# LPC122x register map
File version: 2
Registers are 32-bit, read-write, reset 0x0 unless marked. A register's access mark holds for its fields unless they carry their own. Offsets are from the block's base; [hi:lo] are bit positions; {n}, {i} and the like mark numbered series; 'fields as' and 'values as' point back to an identical list.

## SYSCON — Product name title=UM10441 Chapter title=LPC122x System control (SYSCON) Modification date=8/18/2011 Major revision=2 Minor revision=0
Base 0x40048000
0x00 SYSMEMREMAP — System memory remap
  [1:0] MAP — System memory remap. Value 0x3 is reserved.
    0=BOOT_LOADER_MODE_IN (Boot Loader Mode. Interrupt vectors are re-mapped to Boot ROM.); 1=USER_RAM_MODE_INTER (User RAM Mode. Interrupt vectors are re-mapped to Static RAM.); 2=USER_FLASH_MODE_INT (User Flash Mode. Interrupt vectors are not re-mapped and reside in Flash.)
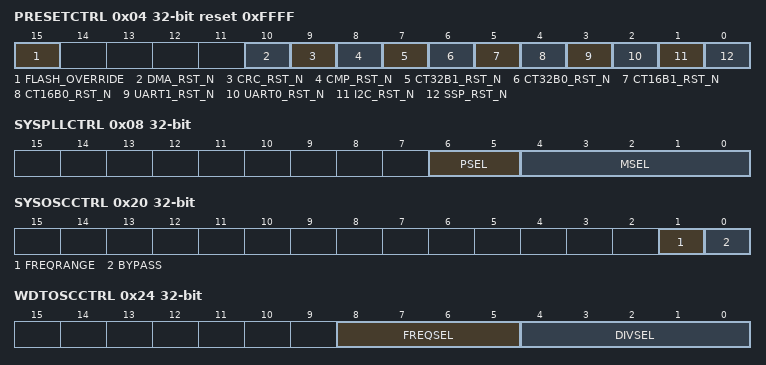
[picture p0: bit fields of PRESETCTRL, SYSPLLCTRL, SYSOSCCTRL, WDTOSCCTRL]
0x04 PRESETCTRL reset 0xFFFF — Peripheral reset control and flash timing overwrite
  [15] FLASH_OVERRIDE — Flash read mode. The default is 1-cycle flash read access. At higher operating frequencies the multi-cycle read mode must be used to allow 2, 3, 4, or 5-cycle read configuration. If multi-cycle read mode is selected, the number of cycles can be configured in the FLASHCFG register (see Table 52).
    0=FLASH_MULTI_CYCLE_RE (Flash multi-cycle read mode.); 1=FLASH_1_CYCLE_READ_M (Flash 1-cycle read mode.)
  [10] DMA_RST_N — Micro DMA reset control
    0=DMA_RESET_ENABLED; 1=DMA_RESET_DE_ASSERTE (DMA reset de-asserted)
  [9] CRC_RST_N — CRC reset control
    0=CRC_RESET_ENABLED; 1=CRC_RESET_DE_ASSERTE (CRC reset de-asserted)
  [8] CMP_RST_N — Comparator reset control
    0=COMPARATOR_RESET_ENA (Comparator reset enabled); 1=COMPARATOR_RESET_DE_ (Comparator reset de-asserted)
  [7] CT32B1_RST_N — 32-bit counter/timer 1 (CT32B1) reset control
    0=CT32B1_RESET_ENABLED; 1=CT32B1_RESET_DE_ASSE (CT32B1 reset de-asserted)
  [6] CT32B0_RST_N — 32-bit counter/timer 0 (CT32B0) reset control
    0=CT32B0_RESET_ENABLED; 1=CT32B0_RESET_DE_ASSE (CT32B0 reset de-asserted)
  [5] CT16B1_RST_N — 16-bit counter/timer 1 (CT16B1) reset control
    0=CT16B1_RESET_ENABLED; 1=CT16B1_RESET_DE_ASSE (CT16B1 reset de-asserted)
  [4] CT16B0_RST_N — 16-bit counter/timer 0 (CT16B0) reset control
    0=CT16B0_RESET_ENABLED; 1=CT16B0_RESET_DE_ASSE (CT16B0 reset de-asserted)
  [3] UART1_RST_N — UART1 reset control
    0=UART1_RESET_ENABLED; 1=UART1_RESET_DE_ASSER (UART1 reset de-asserted)
  [2] UART0_RST_N — UART0 reset control
    0=UART0_RESET_ENABLED; 1=UART0_RESET_DE_ASSER (UART0 reset de-asserted)
  [1] I2C_RST_N — I2C reset control
    0=I2C_RESET_ENABLED; 1=I2C_RESET_DE_ASSERTE (I2C reset de-asserted)
  [0] SSP_RST_N — SSP reset control
    0=SSP_RESET_ENABLED; 1=SSP_RESET_DE_ASSERTE (SSP reset de-asserted)
0x08 SYSPLLCTRL — System PLL control
  [6:5] PSEL — Post divider ratio P. The division ratio is 2xP.
    0=P_EQ_1 (P = 1); 1=P_EQ_2 (P = 2); 2=P_EQ_4 (P = 4); 3=P_EQ_8 (P = 8)
  [4:0] MSEL — Feedback divider value. The division value M is the programmed MSEL value + 1. 00000: Division ratio M = 1 to 11111: Division ratio M = 32
0x0C SYSPLLSTAT ro — System PLL status
  [0] LOCK — PLL lock status
    0=PLL_NOT_LOCKED; 1=PLL_LOCKED
0x20 SYSOSCCTRL — System oscillator control
  [1] FREQRANGE — Determines frequency range for Low-power oscillator.
    0=1__20_MHZ_FREQUENCY (1 - 20 MHz frequency range.); 1=15__25_MHZ_FREQUENC (15 - 25 MHz frequency range)
  [0] BYPASS — Bypass system oscillator
    0=OSCILLATOR_IS_NOT_BY (Oscillator is not bypassed.); 1=BYPASS_ENABLED_PLL_ (Bypass enabled. PLL input (sys_osc_clk) is fed directly from the XTALIN and XTALOUT pins.)
0x24 WDTOSCCTRL — Watchdog oscillator control
  [8:5] FREQSEL — Select watchdog oscillator analog output frequency (Fclkana).
    1=0_5_MHZ; 2=0_8_MHZ; 3=1_1_MHZ; 4=1_4_MHZ; 5=1_6_MHZ; 6=1_8_MHZ; 7=2_0_MHZ; 8=2_2_MHZ; 9=2_4_MHZ; 10=2_6_MHZ; 11=2_7_MHZ; 12=2_9_MHZ; 13=3_1_MHZ; 14=3_2_MHZ; 15=3_4_MHZ
  [4:0] DIVSEL — Select divider for Fclkana. wdt_osc_clk = Fclkana/ (2 x (1 + DIVSEL)) 00000: 2 x (1 + DIVSEL) = 2 00001: 2 x (1 + DIVSEL) = 4 to 11111: 2 x (1 + DIVSEL) = 64
0x28 IRCCTRL reset 0x80 — IRC control
  [7:0] TRIM — Trim value
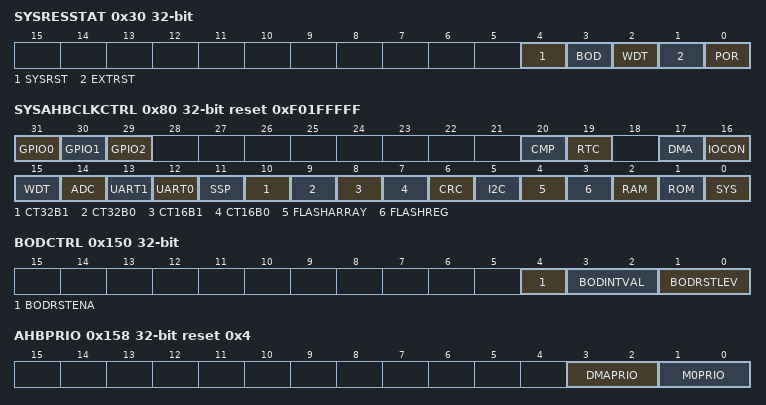
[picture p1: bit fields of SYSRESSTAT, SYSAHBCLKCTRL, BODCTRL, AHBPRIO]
0x30 SYSRESSTAT — System reset status register
  [4] SYSRST — Status of the software system reset.The ARM software reset has the same effect as the hardware reset using the RESET pin.
    0=NO_SYSTEM_RESET_DETE (no System reset detected); 1=SYSTEM_RESET_DETECTE (System reset detected)
  [3] BOD — Status of the Brown-out detect reset
    0=NO_BOD_RESET_DETECTE (no BOD reset detected); 1=BOD_RESET_DETECTED
  [2] WDT — Status of the Watchdog reset
    0=NO_WDT_RESET_DETECTE (no WDT reset detected); 1=WDT_RESET_DETECTED
  [1] EXTRST — reset status
    0=NO_RESET_EVENT_DETEC (no RESET event detected); 1=RESET_DETECTED
  [0] POR — POR reset status
    0=NO_POR_DETECTED; 1=POR_DETECTED
0x40 SYSPLLCLKSEL — System PLL clock source select
  [1:0] SEL — System PLL clock source
    0=IRC_OSCILLATOR; 1=SYSTEM_OSCILLATOR
0x44 SYSPLLCLKUEN — System PLL clock source update enable
  [0] ENA — Enable system PLL clock source update
    0=NO_CHANGE; 1=UPDATE_CLOCK_SOURCE
0x70 MAINCLKSEL — Main clock source select
  [1:0] SEL — Clock source for main clock
    0=IRC_OSCILLATOR; 1=INPUT_CLOCK_TO_SYSTE (Input clock to system PLL); 2=WDT_OSCILLATOR; 3=SYSTEM_PLL_CLOCK_OUT
0x74 MAINCLKUEN — Main clock source update enable
  [0] ENA — Enable main clock source update
    0=NO_CHANGE; 1=UPDATE_CLOCK_SOURCE
0x78 SYSAHBCLKDIV reset 0x1 — System AHB clock divider
  [7:0] DIV — System AHB clock divider values 0: System clock disabled. 1: Divide by 1. to 255: Divide by 255.
0x80 SYSAHBCLKCTRL reset 0xF01FFFFF — System AHB clock control
  [31] GPIO0 — Enables clock for GPIO port 0.
    0=DISABLE; 1=ENABLE
  [30] GPIO1 — Enables clock for GPIO port 1.
    0=DISABLE; 1=ENABLE
  [29] GPIO2 — Enables clock for GPIO port 2.
    0=DISABLE; 1=ENABLE
  [20] CMP — Enables clock for comparator.
    0=DISABLE; 1=ENABLE
  [19] RTC — Enables clock for RTC. If the RTC clock source is disabled, select the RTC clock source first, before re-enabling the RTC through this bit (see Table 58).
    0=DISABLE; 1=ENABLE
  [17] DMA — Enables clock for micro DMA.
    0=DISABLE; 1=ENABLE
  [16] IOCON — Enables clock for IO configuration block.
    0=DISABLE; 1=ENABLE
  [15] WDT — Enables clock for WDT.
    0=DISABLE; 1=ENABLE
  [14] ADC — Enables clock for ADC.
    0=DISABLE; 1=ENABLE
  [13] UART1 — Enables clock for UART1. Note that the UART1 pins must be configured in the IOCON block before the UART1 clock can be enabled.
    0=DISABLE; 1=ENABLE
  [12] UART0 — Enables clock for UART0. Note that the UART0 pins must be configured in the IOCON block before the UART0 clock can be enabled.
    0=DISABLE; 1=ENABLE
  [11] SSP — Enables clock for SSP.
    0=DISABLE; 1=ENABLE
  [10] CT32B1 — Enables clock for 32-bit counter/timer 1.
    0=DISABLE; 1=ENABLE
  [9] CT32B0 — Enables clock for 32-bit counter/timer 0.
    0=DISABLE; 1=ENABLE
  [8] CT16B1 — Enables clock for 16-bit counter/timer 1.
    0=DISABLE; 1=ENABLE
  [7] CT16B0 — Enables clock for 16-bit counter/timer 0.
    0=DISABLE; 1=ENABLE
  [6] CRC — Enables clock for CRC.
    0=DISABLE; 1=ENABLE
  [5] I2C — Enables clock for I2C.
    0=DISABLE; 1=ENABLE
  [4] FLASHARRAY — Enables clock for flash array.
    0=DISABLE; 1=ENABLE
  [3] FLASHREG — Enables clock for flash controller registers.
    0=DISABLE; 1=ENABLE
  [2] RAM — Enables clock for RAM.
    0=DISABLE; 1=ENABLE
  [1] ROM — Enables clock for ROM.
    0=DISABLE; 1=ENABLE
  [0] SYS — Enables clock for AHB to APB bridge, to the AHB matrix, to the Cortex-M0 FCLK and HCLK, to the SysCon, and to the PMU. This bit is read only.
    1=ENABLE
0x94 SSPCLKDIV — SSP clock divder
  [7:0] DIV — SSP0_PCLK clock divider values 0: Disable SSP0_PCLK. 1: Divide by 1. to 255: Divide by 255.
0x98 UART0CLKDIV — UART0 clock divider
  [7:0] DIV — UART0_PCLK clock divider values 0: Disable UART0_PCLK. 1: Divide by 1. to 255: Divide by 255.
0x9C UART1CLKDIV — UART1 clock divider
  [7:0] DIV — UART1_PCLK clock divider values 0: Disable UART1_PCLK. 1: Divide by 1. to 255: Divide by 255.
0xA0 RTCCLKDIV — RTC clock divider
  [7:0] DIV — RTC_PCLK clock divider values 0: Disable RTC_PCLK. 1: Divide by 1. to 255: Divide by 255.
0xE0 CLKOUTCLKSEL — CLKOUT clock source select
  [1:0] SEL — CLKOUT clock source
    0=IRC_OSCILLATOR; 1=SYSTEM_OSCILLATOR; 2=WATCHDOG_OSCILLATOR; 3=MAIN_CLOCK
0xE4 CLKOUTUEN — CLKOUT clock source update enable
  [0] ENA — Enable CLKOUT clock source update
    0=NO_CHANGE; 1=UPDATE_CLOCK_SOURCE
0xE8 CLKOUTDIV — CLKOUT clock divider
  [7:0] DIV — Clock output divider values 0: Disable CLKOUT. 1: Divide by 1. to 255: Divide by 255.
0x100 PIOPORCAP0 ro reset not defined — POR captured PIO status 0
  [31:0] PIOSTAT — Raw reset status input PIO0_31 to PIO2_7
0x104 PIOPORCAP1 ro reset not defined — POR captured PIO status 1
  [31:0] PIOSTAT — Raw reset status input PIO2_8 to PIO2_11
0x134 IOCONFIGCLKDIV6 — Peripheral clock 6 to the IOCONFIG block for programmable glitch filter
  [7:0] DIV — IOCONFIG filter clock divider values 0: Disable IOCONFIGCLK. 1: Divide by 1. to 255: Divide by 255.
0x138 IOCONFIGCLKDIV5 — Peripheral clock 5 to the IOCONFIG block for programmable glitch filter
  fields as IOCONFIGCLKDIV6
0x13C IOCONFIGCLKDIV4 — Peripheral clock 4 to the IOCONFIG block for programmable glitch filter
  fields as IOCONFIGCLKDIV6
0x140 IOCONFIGCLKDIV3 — Peripheral clock 3 to the IOCONFIG block for programmable glitch filter
  fields as IOCONFIGCLKDIV6
0x144 IOCONFIGCLKDIV2 — Peripheral clock 2 to the IOCONFIG block for programmable glitch filter
  fields as IOCONFIGCLKDIV6
0x148 IOCONFIGCLKDIV1 — Peripheral clock 1 to the IOCONFIG block for programmable glitch filter
  fields as IOCONFIGCLKDIV6
0x14C IOCONFIGCLKDIV0 — Peripheral clock 0 to the IOCONFIG block for programmable glitch filter
  fields as IOCONFIGCLKDIV6
0x150 BODCTRL reset not defined — BOD control
  [4] BODRSTENA — BOD reset enable
    0=DISABLE_RESET_FUNCTI (Disable reset function.); 1=ENABLE_RESET_FUNCTIO (Enable reset function.)
  [3:2] BODINTVAL — BOD interrupt level
    1=LEVEL_1 (Level 1:The interrupt assertion threshold voltage is 2.248 V; the interrupt de-assertion threshold voltage is 2.385 V.); 2=LEVEL_2 (Level 2: The interrupt assertion threshold voltage is 2.541 V; the interrupt de-assertion threshold voltage is 2.669 V.); 3=LEVEL_3 (Level 3: The interrupt assertion threshold voltage is 2.828 V; the interrupt de-assertion threshold voltage is 2.929 V.)
  [1:0] BODRSTLEV — BOD reset level
    0=RESERVED_WRITING_00 (Reserved. Writing 00 to these bits will not change the BOD reset level.); 1=LEVEL_1 (Level 1: The reset assertion threshold voltage is 2.038 V; the reset de-assertion threshold voltage is 2.180 V.); 2=LEVEL_2 (Level 2: The reset assertion threshold voltage is 2.336 V; the reset de-assertion threshold voltage is 2.471 V.); 3=LEVEL_3 (Level 3: The reset assertion threshold voltage is 2.624 V; the reset de-assertion threshold voltage is 2.761 V.)
0x154 SYSTCKCAL reset 0x1F — System tick counter calibration
  [25:0] CAL — System tick timer calibration value
0x158 AHBPRIO reset 0x4 — AHB priority setting
  [3:2] DMAPRIO — Priority of the micro DMA controller
  [1:0] M0PRIO — Priority of the ARM Cortex-M0 core
0x170 IRQLATENCY reset 0x10 — IQR delay. Allows trade-off between interrupt latency and determinism.
  [7:0] LATENCY — 8-bit latency value
0x174 INTNMI reset 0x3F — NMI interrupt source configuration control
  [5:0] NMISRC — NMI interrupt source select. Values 0x13 to 0x3E are reserved. 0x0 = I2C interrupt. 0x1 = CT16B0 interrupt. 0x2 = CT16B1 interrupt. 0x3 = CT32B0 interrupt. 0x4 = CT32B1 interrupt. 0x5 = SSP interrupt. 0x6 = UART0 interrupt. 0x7 = UART1 interrupt. 0x8 = Comparator interrupt. 0x9 = ADC interrupt. 0xA = Watchdog timer interrupt. 0xB = I2C interrupt. 0xC = Reserved. 0xD = PIO0 interrupt. 0xE = PIO1 interrupt. 0xF = PIO2 interrupt. 0x10 = PMU wake-up interrupt. 0x11 = DMA interrupt. 0x12 = RTC interrupt. 0x3F = NMI disabled.
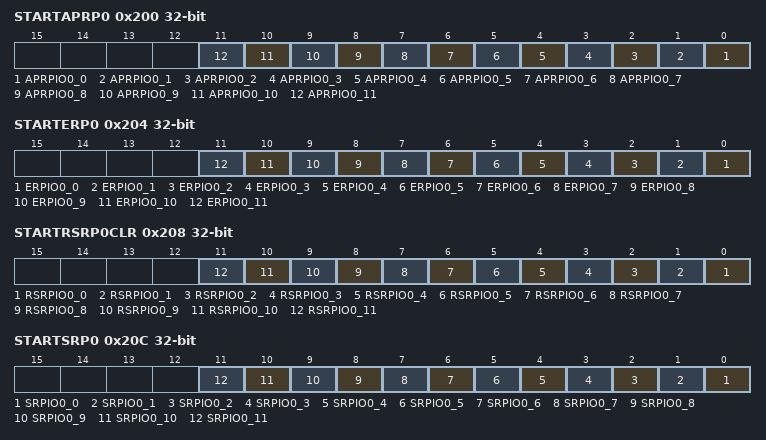
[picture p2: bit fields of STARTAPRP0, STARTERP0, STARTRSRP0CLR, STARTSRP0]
0x200 STARTAPRP0 — Start logic edge control register 0
  [n] APRPIO0_{n} (n=0..11) — Edge select for start logic input n for pin PIO0_{n}. 0 = Falling edge 1 = Rising edge
0x204 STARTERP0 — Start logic signal enable register 0
  [n] ERPIO0_{n} (n=0..11) — Enable start signal for start logic input n for pin PIO0_{n}. 0 = Disabled. 1 = Enabled.
0x208 STARTRSRP0CLR wo — Start logic reset register 0
  [n] RSRPIO0_{n} (n=0..11) — Start signal reset for start logic input n for pin PIO0_{n}. 0 = No effect. 1 = Write: reset start signal.
0x20C STARTSRP0 ro — Start logic status register 0
  [n] SRPIO0_{n} (n=0..11) — Start signal status for start logic input n for pin PIO0_{n}. 0 = No start signal received. 1 = Start signal pending.
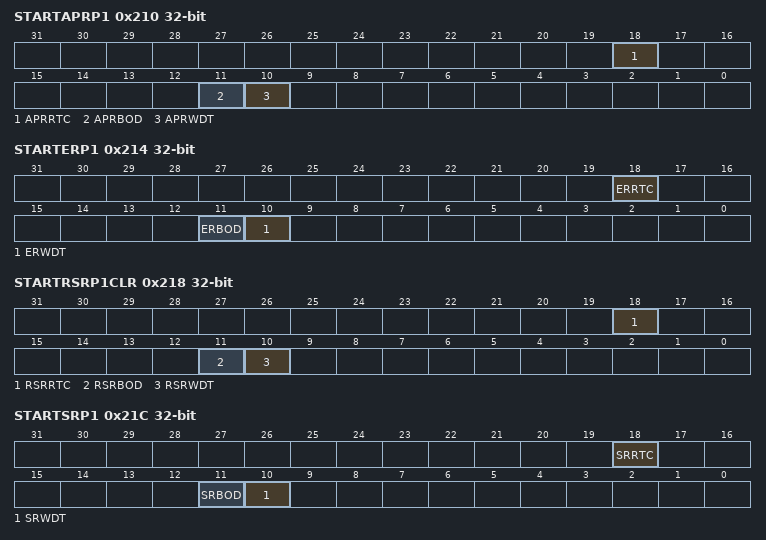
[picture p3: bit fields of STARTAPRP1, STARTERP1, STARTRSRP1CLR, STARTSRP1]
0x210 STARTAPRP1 — Start logic edge control register 1; peripheral interrupts
  [18] APRRTC — Edge select for start logic interrupt RTC. 0 = Falling edge. 1 = Rising edge.
  [11] APRBOD — Edge select for start logic interrupt BOD. 0 = Falling edge. 1 = Rising edge.
  [10] APRWDT — Edge select for start logic interrupt WDT. 0 = Falling edge. 1 = Rising edge.
0x214 STARTERP1 — Start logic signal enable register 1; peripheral interrupts
  [18] ERRTC — Enable start signal for start logic interrupt RTC. 0 = Disabled. 1 = Enabled.
  [11] ERBOD — Enable start signal for start logic interrupt BOD. 0 = Disabled. 1 = Enabled.
  [10] ERWDT — Enable start signal for start logic interrupt WDT. 0 = Disabled. 1 = Enabled.
0x218 STARTRSRP1CLR wo — Start logic reset register 1; peripheral interrupts
  [18] RSRRTC — Start signal reset for start logic interrupt RTC. 0 = No effect. 1 = Write: reset start signal.
  [11] RSRBOD — Start signal reset for start logic interrupt BOD. 0 = No effect. 1 = Write: reset start signal.
  [10] RSRWDT — Start signal reset for start logic interrupt WDT. 0 = No effect. 1 = Write: reset start signal.
0x21C STARTSRP1 ro — Start logic status register 1; peripheral interrupts
  [18] SRRTC — Start signal status for start logic interrupt RTC. 0 = No start signal received. 1 = Start signal pending.
  [11] SRBOD — Start signal status for start logic interrupt BOD. 0 = No start signal received. 1 = Start signal pending.
  [10] SRWDT — Start signal status for start logic interrupt WDT. 0 = No start signal received. 1 = Start signal pending.
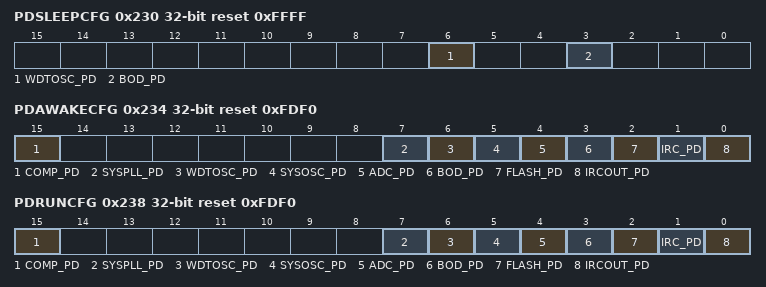
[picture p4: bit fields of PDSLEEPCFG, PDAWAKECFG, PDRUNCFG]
0x230 PDSLEEPCFG reset 0xFFFF — Power-down states in Deep-sleep mode
  [6] WDTOSC_PD — Watchdog oscillator power-down control in Deep-sleep mode
    0=POWERED; 1=POWERED_DOWN_MUST_B (Powered down. Must be changed to 0 before the WDLOCKCLK bit is set in the WDMODE register. See Table 266.)
  [3] BOD_PD — BOD power-down control in Deep-sleep mode
    0=POWERED; 1=POWERED_DOWN
0x234 PDAWAKECFG reset 0xFDF0 — Power-down states after wake-up from Deep-sleep mode
  [all] fields
    0=POWERED; 1=POWERED_DOWN
  [15] COMP_PD — Comparator power-down wake-up configuration
  [7] SYSPLL_PD — System PLL wake-up configuration
  [6] WDTOSC_PD — Watchdog oscillator wake-up configuration
  [5] SYSOSC_PD — System oscillator wake-up configuration
  [4] ADC_PD — ADC wake-up configuration
  [3] BOD_PD — BOD wake-up configuration
  [2] FLASH_PD — Flash wake-up configuration
  [1] IRC_PD — IRC oscillator power-down wake-up configuration
  [0] IRCOUT_PD — IRC oscillator output wake-up configuration
0x238 PDRUNCFG reset 0xFDF0 — Power-down configuration register
  [all] fields
    0=POWERED; 1=POWERED_DOWN
  [15] COMP_PD — Comparator power-down
  [7] SYSPLL_PD — System PLL power-down
  [6] WDTOSC_PD — Watchdog oscillator power-down
  [5] SYSOSC_PD — System oscillator power-down
  [4] ADC_PD — ADC power-down
  [3] BOD_PD — BOD power-down
  [2] FLASH_PD — Flash power-down
  [1] IRC_PD — IRC oscillator power-down
  [0] IRCOUT_PD — IRC oscillator output power-down
0x3F4 DEVICE_ID ro reset not defined
  [31:0] DEVICEID — Device ID for LPC122x parts: LPC12D27FBD100/301 = 0x3670 002B LPC1227FBD64/301 = 0x3670 002B LPC1227FBD48/301 = 0x3670 002B LPC1226FBD64/301 = 0x3660 002B LPC1226FBD48/301 = 0x3660 002B LPC1225FBD64/321 = 0x3652 002B LPC1225FBD64/301 = 0x3650 002B LPC1225FBD48/321 = 0x3652 002B LPC1225FBD48/301 = 0x3650 002B LPC1224FBD64/121 = 0x3642 C02B LPC1224FBD64/101 = 0x3640 C02B LPC1224FBD48/121 = 0x3642 C02B LPC1224FBD48/101 = 0x3640 C02B
